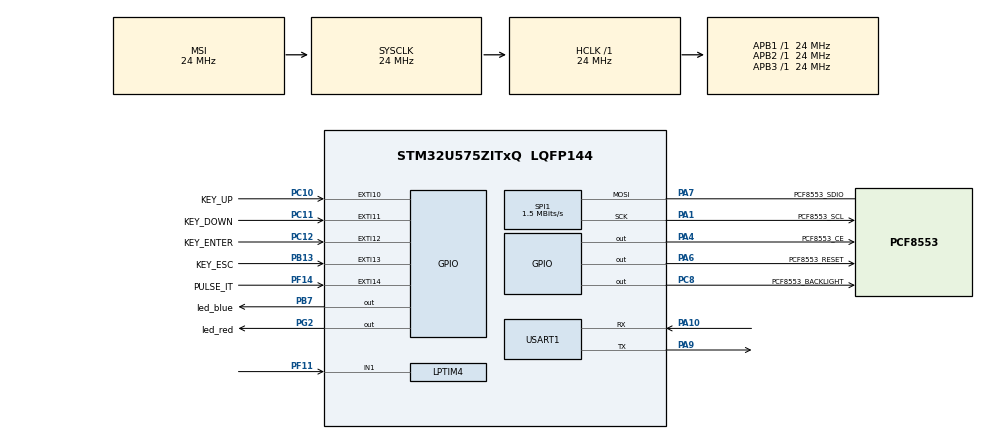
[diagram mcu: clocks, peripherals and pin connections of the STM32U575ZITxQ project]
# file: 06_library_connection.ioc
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ADC1.Channel-0\#ChannelRegularConversion=ADC_CHANNEL_TEMPSENSOR
ADC1.ClockPrescaler=ADC_CLOCK_ASYNC_DIV2
ADC1.EnableRegularConversion=ENABLE
ADC1.MonitoredBy-0\#ChannelRegularConversion=__NULL
ADC1.NbrOfConversion=1
ADC1.NbrOfConversionFlag=1
ADC1.OffsetNumber-0\#ChannelRegularConversion=ADC_OFFSET_NONE
ADC1.Rank-0\#ChannelRegularConversion=1
ADC1.Resolution=ADC_RESOLUTION_12B
ADC1.SamplingTime-0\#ChannelRegularConversion=ADC_SAMPLETIME_391CYCLES_5
ADC1.master=1
CORTEX_M33_NS.userName=CORTEX_M33
LPTIM1.ClockPrescaler=LPTIM_PRESCALER_DIV16
Mcu.Family=STM32U5
Mcu.Name=STM32U575ZITxQ
Mcu.Package=LQFP144
NVIC.EXTI10_IRQn=true\:5\:0\:true\:false\:true\:false\:true\:true\:true
NVIC.EXTI11_IRQn=true\:5\:0\:true\:false\:true\:false\:true\:true\:true
NVIC.EXTI12_IRQn=true\:5\:0\:true\:false\:true\:false\:true\:true\:true
NVIC.EXTI13_IRQn=true\:5\:0\:true\:false\:true\:false\:true\:true\:true
NVIC.EXTI14_IRQn=true\:5\:0\:true\:false\:true\:false\:true\:true\:true
NVIC.LPTIM1_IRQn=true\:0\:0\:false\:false\:true\:false\:true\:true\:true
NVIC.PriorityGroup=NVIC_PRIORITYGROUP_4
NVIC.RTC_IRQn=true\:0\:0\:false\:false\:true\:false\:true\:true\:true
NVIC.TIM6_IRQn=true\:15\:0\:false\:false\:true\:false\:false\:true\:true
NVIC.TimeBase=TIM6_IRQn
NVIC.TimeBaseIP=TIM6
PA1.GPIO_Label=PCF8553_SCL
PA1.Mode=Simplex_Bidirectional_Master
PA1.Signal=SPI1_SCK
PA10.Mode=Asynchronous
PA10.Signal=USART1_RX
PA4.GPIO_Label=PCF8553_CE
PA4.Signal=GPIO_Output
PA6.GPIO_Label=PCF8553_RESET
PA6.Signal=GPIO_Output
PA7.GPIO_Label=PCF8553_SDIO
PA7.Mode=Simplex_Bidirectional_Master
PA7.Signal=SPI1_MOSI
PA9.Mode=Asynchronous
PA9.Signal=USART1_TX
PB13.GPIO_Label=KEY_ESC
PB13.Signal=GPXTI13
PB7.GPIO_Label=led_blue
PB7.Signal=GPIO_Output
PC10.GPIO_Label=KEY_UP
PC10.Signal=GPXTI10
PC11.GPIO_Label=KEY_DOWN
PC11.Signal=GPXTI11
PC12.GPIO_Label=KEY_ENTER
PC12.Signal=GPXTI12
PC14-OSC32_IN\ (PC14).Mode=LSE-External-Oscillator
PC14-OSC32_IN\ (PC14).Signal=RCC_OSC32_IN
PC15-OSC32_OUT\ (PC15).Mode=LSE-External-Oscillator
PC15-OSC32_OUT\ (PC15).Signal=RCC_OSC32_OUT
PC8.GPIO_Label=PCF8553_BACKLIGHT
PC8.Signal=GPIO_Output
PF11.Mode=Counts_external_clock_with_synchro_01_occur1
PF11.Signal=LPTIM4_IN1
PF14.GPIO_Label=PULSE_IT
PF14.GPIO_ModeDefaultEXTI=GPIO_MODE_IT_FALLING
PF14.Signal=GPXTI14
PG2.GPIO_Label=led_red
PG2.Signal=GPIO_Output
PWR.PowerMode=PWR_SMPS_SUPPLY
ProjectManager.HeapSize=0x200
ProjectManager.StackSize=0x400
ProjectManager.TargetToolchain=STM32CubeIDE
RCC.ADCCLockSelection=RCC_ADCDACCLKSOURCE_SYSCLK
RCC.ADCFreq_Value=24000000
RCC.AHBFreq_Value=24000000
RCC.APB1Freq_Value=24000000
RCC.APB1TimFreq_Value=24000000
RCC.APB2Freq_Value=24000000
RCC.APB2TimFreq_Value=24000000
RCC.APB3Freq_Value=24000000
RCC.CortexFreq_Value=24000000
RCC.EPOD_VALUE=24000000
RCC.HCLKFreq_Value=24000000
RCC.HSE_VALUE=16000000
RCC.HSI48_VALUE=48000000
RCC.HSI_VALUE=16000000
RCC.LPTIM1CLockSelectionVirtual=RCC_LPTIM1CLKSOURCE_LSE
RCC.LPTIM3CLockSelectionVirtual=RCC_LPTIM34CLKSOURCE_LSE
RCC.LSIDIV_VALUE=32000
RCC.MSIClockRange=RCC_MSIRANGE_1
RCC.MSI_VALUE=24000000
RCC.RTCClockSelection=RCC_RTCCLKSOURCE_LSE
RCC.SYSCLKFreq_VALUE=24000000
RCC.USART1CLockSelectionVirtual=RCC_USART1CLKSOURCE_SYSCLK
RCC.USBFreq_Value=48000000
RCC.VCOOutputFreq_Value=3096000000
RTC.Date=30
RTC.Hours=9
RTC.Minutes=52
RTC.Month=RTC_MONTH_MAY
RTC.WakeUpCounter-WakeUp=4096
RTC.WeekDay=RTC_WEEKDAY_TUESDAY
RTC.Year=23
SPI1.BaudRatePrescaler=SPI_BAUDRATEPRESCALER_16
SPI1.CalculateBaudRate=1.5 MBits/s
SPI1.DataSize=SPI_DATASIZE_8BIT
SPI1.Direction=SPI_DIRECTION_1LINE
SPI1.Mode=SPI_MODE_MASTER
SPI1.NSSPMode=SPI_NSS_PULSE_DISABLE
SPI1.VirtualType=VM_MASTER
THREADX.TX_LOW_POWER=1
THREADX.TX_LOW_POWER_TICKLESS=0
THREADX.TX_LOW_POWER_TIMER_SETUP=app_threadx_lowpower_timer_setup
USART1.VirtualMode-Asynchronous=VM_ASYNC
VP_ADC1_TempSens_Input.Mode=IN-TempSens
VP_ADC1_Vref_Input.Mode=IN-Vrefint
VP_ICACHE_VS_ICACHE.Mode=DirectMappedCache
VP_LPTIM1_VS_LPTIM_counterModeInternalClock.Mode=Counts__internal_clock_event_00
VP_LPTIM3_VS_LPTIM_counterModeInternalClock.Mode=Counts__internal_clock_event_00
VP_PWR_VS_DBSignals.Mode=DisableDeadBatterySignals
VP_PWR_VS_LPOM.Mode=PowerOptimisation
VP_RTC_VS_RTC_Activate.Mode=RTC_Enabled
VP_RTC_VS_RTC_Calendar.Mode=RTC_Calendar
VP_RTC_VS_RTC_WakeUp_intern.Mode=WakeUp
VP_SYS_VS_tim6.Mode=TIM6
VP_THREADX_VS_RTOSJjThreadXJjCoreJjDefault.Mode=Core_Default
VP_THREADX_VS_RTOSJjThreadXJjLow_Power_Support.Mode=Low_Power_Support
VP_THREADX_VS_RTOSJjThreadXJjTraceX_SupportJjDefault.Mode=TraceX_Support_Default
board=custom

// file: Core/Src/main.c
/* USER CODE BEGIN Header */
/**
  ******************************************************************************
  * @file           : main.c
  * @brief          : Main program body
  ******************************************************************************
  * @attention
  *
  * Copyright (c) 2023 STMicroelectronics.
  * All rights reserved.
  *
  * This software is licensed under terms that can be found in the LICENSE file
  * in the root directory of this software component.
  * If no LICENSE file comes with this software, it is provided AS-IS.
  *
  ******************************************************************************
  */
/* USER CODE END Header */
#include "app_threadx.h"
#include "main.h"

ADC_HandleTypeDef hadc1;

LPTIM_HandleTypeDef hlptim1;
LPTIM_HandleTypeDef hlptim3;
LPTIM_HandleTypeDef hlptim4;

RTC_HandleTypeDef hrtc;

SPI_HandleTypeDef hspi1;

UART_HandleTypeDef huart1;

void SystemClock_Config(void);
static void SystemPower_Config(void);
static void MX_GPIO_Init(void);
static void MX_ADC1_Init(void);
static void MX_ICACHE_Init(void);
static void MX_LPTIM1_Init(void);
static void MX_LPTIM3_Init(void);
static void MX_LPTIM4_Init(void);
static void MX_RTC_Init(void);
static void MX_SPI1_Init(void);
static void MX_USART1_UART_Init(void);

int main(void)
{

  /* MCU Configuration--------------------------------------------------------*/

  /* Reset of all peripherals, Initializes the Flash interface and the Systick. */
  HAL_Init();

  /* Configure the system clock */
  SystemClock_Config();

  /* Configure the System Power */
  SystemPower_Config();

  /* Initialize all configured peripherals */
  MX_GPIO_Init();
  MX_ADC1_Init();
  MX_ICACHE_Init();
  MX_LPTIM1_Init();
  MX_LPTIM3_Init();
  MX_LPTIM4_Init();
  MX_RTC_Init();
  MX_SPI1_Init();
  MX_USART1_UART_Init();
  /* USER CODE BEGIN 2 */

  __HAL_RCC_RTCAPB_CLKAM_ENABLE();
  HAL_LPTIM_Counter_Start(&hlptim1);
  /* USER CODE END 2 */

  MX_ThreadX_Init();

  /* We should never get here as control is now taken by the scheduler */
  /* Infinite loop */
  while (1)
  {

  }
}

void SystemClock_Config(void)
{
  RCC_OscInitTypeDef RCC_OscInitStruct = {0};
  RCC_ClkInitTypeDef RCC_ClkInitStruct = {0};

  /** Configure the main internal regulator output voltage
  */
  if (HAL_PWREx_ControlVoltageScaling(PWR_REGULATOR_VOLTAGE_SCALE4) != HAL_OK)
  {
    Error_Handler();
  }

  /** Configure LSE Drive Capability
  */
  HAL_PWR_EnableBkUpAccess();
  __HAL_RCC_LSEDRIVE_CONFIG(RCC_LSEDRIVE_LOW);

  /** Initializes the CPU, AHB and APB buses clocks
  */
  RCC_OscInitStruct.OscillatorType = RCC_OSCILLATORTYPE_LSE|RCC_OSCILLATORTYPE_MSI;
  RCC_OscInitStruct.LSEState = RCC_LSE_ON;
  RCC_OscInitStruct.MSIState = RCC_MSI_ON;
  RCC_OscInitStruct.MSICalibrationValue = RCC_MSICALIBRATION_DEFAULT;
  RCC_OscInitStruct.MSIClockRange = RCC_MSIRANGE_1;
  RCC_OscInitStruct.PLL.PLLState = RCC_PLL_NONE;
  if (HAL_RCC_OscConfig(&RCC_OscInitStruct) != HAL_OK)
  {
    Error_Handler();
  }

  /** Initializes the CPU, AHB and APB buses clocks
  */
  RCC_ClkInitStruct.ClockType = RCC_CLOCKTYPE_HCLK|RCC_CLOCKTYPE_SYSCLK
                              |RCC_CLOCKTYPE_PCLK1|RCC_CLOCKTYPE_PCLK2
                              |RCC_CLOCKTYPE_PCLK3;
  RCC_ClkInitStruct.SYSCLKSource = RCC_SYSCLKSOURCE_MSI;
  RCC_ClkInitStruct.AHBCLKDivider = RCC_SYSCLK_DIV1;
  RCC_ClkInitStruct.APB1CLKDivider = RCC_HCLK_DIV1;
  RCC_ClkInitStruct.APB2CLKDivider = RCC_HCLK_DIV1;
  RCC_ClkInitStruct.APB3CLKDivider = RCC_HCLK_DIV1;

  if (HAL_RCC_ClockConfig(&RCC_ClkInitStruct, FLASH_LATENCY_1) != HAL_OK)
  {
    Error_Handler();
  }
}

/**
  * @brief Power Configuration
  * @retval None
  */
static void SystemPower_Config(void)
{
  HAL_PWREx_EnableVddIO2();

  /*
   * Disable the internal Pull-Up in Dead Battery pins of UCPD peripheral
   */
  HAL_PWREx_DisableUCPDDeadBattery();

  /*
   * Switch to SMPS regulator instead of LDO
   */
  if (HAL_PWREx_ConfigSupply(PWR_SMPS_SUPPLY) != HAL_OK)
  {
    Error_Handler();
  }
}

static void MX_ADC1_Init(void)
{

  ADC_ChannelConfTypeDef sConfig = {0};

  /** Common config
  */
  hadc1.Instance = ADC1;
  hadc1.Init.ClockPrescaler = ADC_CLOCK_ASYNC_DIV2;
  hadc1.Init.Resolution = ADC_RESOLUTION_12B;
  hadc1.Init.GainCompensation = 0;
  hadc1.Init.ScanConvMode = ADC_SCAN_DISABLE;
  hadc1.Init.EOCSelection = ADC_EOC_SINGLE_CONV;
  hadc1.Init.LowPowerAutoWait = DISABLE;
  hadc1.Init.ContinuousConvMode = DISABLE;
  hadc1.Init.NbrOfConversion = 1;
  hadc1.Init.DiscontinuousConvMode = DISABLE;
  hadc1.Init.ExternalTrigConv = ADC_SOFTWARE_START;
  hadc1.Init.ExternalTrigConvEdge = ADC_EXTERNALTRIGCONVEDGE_NONE;
  hadc1.Init.DMAContinuousRequests = DISABLE;
  hadc1.Init.TriggerFrequencyMode = ADC_TRIGGER_FREQ_HIGH;
  hadc1.Init.Overrun = ADC_OVR_DATA_PRESERVED;
  hadc1.Init.LeftBitShift = ADC_LEFTBITSHIFT_NONE;
  hadc1.Init.ConversionDataManagement = ADC_CONVERSIONDATA_DR;
  hadc1.Init.OversamplingMode = DISABLE;
  if (HAL_ADC_Init(&hadc1) != HAL_OK)
  {
    Error_Handler();
  }

  /** Configure Regular Channel
  */
  sConfig.Channel = ADC_CHANNEL_TEMPSENSOR;
  sConfig.Rank = ADC_REGULAR_RANK_1;
  sConfig.SamplingTime = ADC_SAMPLETIME_391CYCLES_5;
  sConfig.SingleDiff = ADC_SINGLE_ENDED;
  sConfig.OffsetNumber = ADC_OFFSET_NONE;
  sConfig.Offset = 0;
  if (HAL_ADC_ConfigChannel(&hadc1, &sConfig) != HAL_OK)
  {
    Error_Handler();
  }

}

static void MX_ICACHE_Init(void)
{

  /** Enable instruction cache in 1-way (direct mapped cache)
  */
  if (HAL_ICACHE_ConfigAssociativityMode(ICACHE_1WAY) != HAL_OK)
  {
    Error_Handler();
  }
  if (HAL_ICACHE_Enable() != HAL_OK)
  {
    Error_Handler();
  }

}

static void MX_LPTIM1_Init(void)
{

  hlptim1.Instance = LPTIM1;
  hlptim1.Init.Clock.Source = LPTIM_CLOCKSOURCE_APBCLOCK_LPOSC;
  hlptim1.Init.Clock.Prescaler = LPTIM_PRESCALER_DIV16;
  hlptim1.Init.Trigger.Source = LPTIM_TRIGSOURCE_SOFTWARE;
  hlptim1.Init.Period = 65535;
  hlptim1.Init.UpdateMode = LPTIM_UPDATE_IMMEDIATE;
  hlptim1.Init.CounterSource = LPTIM_COUNTERSOURCE_INTERNAL;
  hlptim1.Init.Input1Source = LPTIM_INPUT1SOURCE_GPIO;
  hlptim1.Init.Input2Source = LPTIM_INPUT2SOURCE_GPIO;
  hlptim1.Init.RepetitionCounter = 0;
  if (HAL_LPTIM_Init(&hlptim1) != HAL_OK)
  {
    Error_Handler();
  }
  /* USER CODE BEGIN LPTIM1_Init 2 */

  /*
   * To run in stop mode the LPBAM low-power backgroung autonomous mode must be
   * configured
   *
   */
  __HAL_RCC_LPTIM1_CLKAM_ENABLE();
  __HAL_RCC_LPDMA1_CLKAM_ENABLE();
  __HAL_RCC_SRAM4_CLKAM_ENABLE();

  /* USER CODE END LPTIM1_Init 2 */

}

static void MX_LPTIM3_Init(void)
{

  hlptim3.Instance = LPTIM3;
  hlptim3.Init.Clock.Source = LPTIM_CLOCKSOURCE_APBCLOCK_LPOSC;
  hlptim3.Init.Clock.Prescaler = LPTIM_PRESCALER_DIV1;
  hlptim3.Init.Trigger.Source = LPTIM_TRIGSOURCE_SOFTWARE;
  hlptim3.Init.Period = 65535;
  hlptim3.Init.UpdateMode = LPTIM_UPDATE_IMMEDIATE;
  hlptim3.Init.CounterSource = LPTIM_COUNTERSOURCE_INTERNAL;
  hlptim3.Init.Input1Source = LPTIM_INPUT1SOURCE_GPIO;
  hlptim3.Init.Input2Source = LPTIM_INPUT2SOURCE_GPIO;
  hlptim3.Init.RepetitionCounter = 0;
  if (HAL_LPTIM_Init(&hlptim3) != HAL_OK)
  {
    Error_Handler();
  }
  /* USER CODE BEGIN LPTIM3_Init 2 */
  __HAL_RCC_LPTIM3_CLKAM_ENABLE();
  /* USER CODE END LPTIM3_Init 2 */

}

static void MX_LPTIM4_Init(void)
{

  hlptim4.Instance = LPTIM4;
  hlptim4.Init.Clock.Source = LPTIM_CLOCKSOURCE_APBCLOCK_LPOSC;
  hlptim4.Init.Clock.Prescaler = LPTIM_PRESCALER_DIV1;
  hlptim4.Init.UltraLowPowerClock.Polarity = LPTIM_CLOCKPOLARITY_RISING;
  hlptim4.Init.UltraLowPowerClock.SampleTime = LPTIM_CLOCKSAMPLETIME_DIRECTTRANSITION;
  hlptim4.Init.Trigger.Source = LPTIM_TRIGSOURCE_SOFTWARE;
  hlptim4.Init.Period = 65535;
  hlptim4.Init.UpdateMode = LPTIM_UPDATE_IMMEDIATE;
  hlptim4.Init.CounterSource = LPTIM_COUNTERSOURCE_EXTERNAL;
  hlptim4.Init.Input1Source = LPTIM_INPUT1SOURCE_GPIO;
  hlptim4.Init.Input2Source = LPTIM_INPUT2SOURCE_GPIO;
  hlptim4.Init.RepetitionCounter = 0;
  if (HAL_LPTIM_Init(&hlptim4) != HAL_OK)
  {
    Error_Handler();
  }
  /* USER CODE BEGIN LPTIM4_Init 2 */
  __HAL_RCC_LPTIM4_CLKAM_ENABLE();
  /* USER CODE END LPTIM4_Init 2 */

}

static void MX_RTC_Init(void)
{

  RTC_PrivilegeStateTypeDef privilegeState = {0};
  RTC_TimeTypeDef sTime = {0};
  RTC_DateTypeDef sDate = {0};

  /** Initialize RTC Only
  */
  hrtc.Instance = RTC;
  hrtc.Init.HourFormat = RTC_HOURFORMAT_24;
  hrtc.Init.AsynchPrediv = 127;
  hrtc.Init.SynchPrediv = 255;
  hrtc.Init.OutPut = RTC_OUTPUT_DISABLE;
  hrtc.Init.OutPutRemap = RTC_OUTPUT_REMAP_NONE;
  hrtc.Init.OutPutPolarity = RTC_OUTPUT_POLARITY_HIGH;
  hrtc.Init.OutPutType = RTC_OUTPUT_TYPE_OPENDRAIN;
  hrtc.Init.OutPutPullUp = RTC_OUTPUT_PULLUP_NONE;
  hrtc.Init.BinMode = RTC_BINARY_NONE;
  if (HAL_RTC_Init(&hrtc) != HAL_OK)
  {
    Error_Handler();
  }
  privilegeState.rtcPrivilegeFull = RTC_PRIVILEGE_FULL_NO;
  privilegeState.backupRegisterPrivZone = RTC_PRIVILEGE_BKUP_ZONE_NONE;
  privilegeState.backupRegisterStartZone2 = RTC_BKP_DR0;
  privilegeState.backupRegisterStartZone3 = RTC_BKP_DR0;
  if (HAL_RTCEx_PrivilegeModeSet(&hrtc, &privilegeState) != HAL_OK)
  {
    Error_Handler();
  }

  /** Initialize RTC and set the Time and Date
  */
  sTime.Hours = 0x9;
  sTime.Minutes = 0x52;
  sTime.Seconds = 0x0;
  sTime.DayLightSaving = RTC_DAYLIGHTSAVING_NONE;
  sTime.StoreOperation = RTC_STOREOPERATION_RESET;
  if (HAL_RTC_SetTime(&hrtc, &sTime, RTC_FORMAT_BCD) != HAL_OK)
  {
    Error_Handler();
  }
  sDate.WeekDay = RTC_WEEKDAY_TUESDAY;
  sDate.Month = RTC_MONTH_MAY;
  sDate.Date = 0x30;
  sDate.Year = 0x23;

  if (HAL_RTC_SetDate(&hrtc, &sDate, RTC_FORMAT_BCD) != HAL_OK)
  {
    Error_Handler();
  }

  /** Enable the WakeUp
  */
  if (HAL_RTCEx_SetWakeUpTimer_IT(&hrtc, 4096, RTC_WAKEUPCLOCK_RTCCLK_DIV16, 0) != HAL_OK)
  {
    Error_Handler();
  }

}

static void MX_SPI1_Init(void)
{

  SPI_AutonomousModeConfTypeDef HAL_SPI_AutonomousMode_Cfg_Struct = {0};

  /* SPI1 parameter configuration*/
  hspi1.Instance = SPI1;
  hspi1.Init.Mode = SPI_MODE_MASTER;
  hspi1.Init.Direction = SPI_DIRECTION_1LINE;
  hspi1.Init.DataSize = SPI_DATASIZE_8BIT;
  hspi1.Init.CLKPolarity = SPI_POLARITY_LOW;
  hspi1.Init.CLKPhase = SPI_PHASE_1EDGE;
  hspi1.Init.NSS = SPI_NSS_SOFT;
  hspi1.Init.BaudRatePrescaler = SPI_BAUDRATEPRESCALER_16;
  hspi1.Init.FirstBit = SPI_FIRSTBIT_MSB;
  hspi1.Init.TIMode = SPI_TIMODE_DISABLE;
  hspi1.Init.CRCCalculation = SPI_CRCCALCULATION_DISABLE;
  hspi1.Init.CRCPolynomial = 0x7;
  hspi1.Init.NSSPMode = SPI_NSS_PULSE_DISABLE;
  hspi1.Init.NSSPolarity = SPI_NSS_POLARITY_LOW;
  hspi1.Init.FifoThreshold = SPI_FIFO_THRESHOLD_01DATA;
  hspi1.Init.MasterSSIdleness = SPI_MASTER_SS_IDLENESS_00CYCLE;
  hspi1.Init.MasterInterDataIdleness = SPI_MASTER_INTERDATA_IDLENESS_00CYCLE;
  hspi1.Init.MasterReceiverAutoSusp = SPI_MASTER_RX_AUTOSUSP_DISABLE;
  hspi1.Init.MasterKeepIOState = SPI_MASTER_KEEP_IO_STATE_DISABLE;
  hspi1.Init.IOSwap = SPI_IO_SWAP_DISABLE;
  hspi1.Init.ReadyMasterManagement = SPI_RDY_MASTER_MANAGEMENT_INTERNALLY;
  hspi1.Init.ReadyPolarity = SPI_RDY_POLARITY_HIGH;
  if (HAL_SPI_Init(&hspi1) != HAL_OK)
  {
    Error_Handler();
  }
  HAL_SPI_AutonomousMode_Cfg_Struct.TriggerState = SPI_AUTO_MODE_DISABLE;
  HAL_SPI_AutonomousMode_Cfg_Struct.TriggerSelection = SPI_GRP1_GPDMA_CH0_TCF_TRG;
  HAL_SPI_AutonomousMode_Cfg_Struct.TriggerPolarity = SPI_TRIG_POLARITY_RISING;
  if (HAL_SPIEx_SetConfigAutonomousMode(&hspi1, &HAL_SPI_AutonomousMode_Cfg_Struct) != HAL_OK)
  {
    Error_Handler();
  }

}

static void MX_USART1_UART_Init(void)
{

  huart1.Instance = USART1;
  huart1.Init.BaudRate = 115200;
  huart1.Init.WordLength = UART_WORDLENGTH_8B;
  huart1.Init.StopBits = UART_STOPBITS_1;
  huart1.Init.Parity = UART_PARITY_NONE;
  huart1.Init.Mode = UART_MODE_TX_RX;
  huart1.Init.HwFlowCtl = UART_HWCONTROL_NONE;
  huart1.Init.OverSampling = UART_OVERSAMPLING_16;
  huart1.Init.OneBitSampling = UART_ONE_BIT_SAMPLE_DISABLE;
  huart1.Init.ClockPrescaler = UART_PRESCALER_DIV1;
  huart1.AdvancedInit.AdvFeatureInit = UART_ADVFEATURE_NO_INIT;
  if (HAL_UART_Init(&huart1) != HAL_OK)
  {
    Error_Handler();
  }
  if (HAL_UARTEx_SetTxFifoThreshold(&huart1, UART_TXFIFO_THRESHOLD_1_8) != HAL_OK)
  {
    Error_Handler();
  }
  if (HAL_UARTEx_SetRxFifoThreshold(&huart1, UART_RXFIFO_THRESHOLD_1_8) != HAL_OK)
  {
    Error_Handler();
  }
  if (HAL_UARTEx_DisableFifoMode(&huart1) != HAL_OK)
  {
    Error_Handler();
  }

}

static void MX_GPIO_Init(void)
{
  GPIO_InitTypeDef GPIO_InitStruct = {0};

  /* GPIO Ports Clock Enable */
  __HAL_RCC_GPIOC_CLK_ENABLE();
  __HAL_RCC_GPIOA_CLK_ENABLE();
  __HAL_RCC_GPIOF_CLK_ENABLE();
  __HAL_RCC_GPIOB_CLK_ENABLE();
  __HAL_RCC_GPIOG_CLK_ENABLE();

  /*Configure GPIO pin Output Level */
  HAL_GPIO_WritePin(GPIOA, PCF8553_CE_Pin|PCF8553_RESET_Pin, GPIO_PIN_RESET);

  /*Configure GPIO pin Output Level */
  HAL_GPIO_WritePin(led_red_GPIO_Port, led_red_Pin, GPIO_PIN_RESET);

  /*Configure GPIO pin Output Level */
  HAL_GPIO_WritePin(PCF8553_BACKLIGHT_GPIO_Port, PCF8553_BACKLIGHT_Pin, GPIO_PIN_RESET);

  /*Configure GPIO pin Output Level */
  HAL_GPIO_WritePin(led_blue_GPIO_Port, led_blue_Pin, GPIO_PIN_RESET);

  /*Configure GPIO pins : PCF8553_CE_Pin PCF8553_RESET_Pin */
  GPIO_InitStruct.Pin = PCF8553_CE_Pin|PCF8553_RESET_Pin;
  GPIO_InitStruct.Mode = GPIO_MODE_OUTPUT_PP;
  GPIO_InitStruct.Pull = GPIO_NOPULL;
  GPIO_InitStruct.Speed = GPIO_SPEED_FREQ_LOW;
  HAL_GPIO_Init(GPIOA, &GPIO_InitStruct);

  /*Configure GPIO pin : PULSE_IT_Pin */
  GPIO_InitStruct.Pin = PULSE_IT_Pin;
  GPIO_InitStruct.Mode = GPIO_MODE_IT_FALLING;
  GPIO_InitStruct.Pull = GPIO_NOPULL;
  HAL_GPIO_Init(PULSE_IT_GPIO_Port, &GPIO_InitStruct);

  /*Configure GPIO pin : KEY_ESC_Pin */
  GPIO_InitStruct.Pin = KEY_ESC_Pin;
  GPIO_InitStruct.Mode = GPIO_MODE_IT_RISING;
  GPIO_InitStruct.Pull = GPIO_NOPULL;
  HAL_GPIO_Init(KEY_ESC_GPIO_Port, &GPIO_InitStruct);

  /*Configure GPIO pin : led_red_Pin */
  GPIO_InitStruct.Pin = led_red_Pin;
  GPIO_InitStruct.Mode = GPIO_MODE_OUTPUT_PP;
  GPIO_InitStruct.Pull = GPIO_NOPULL;
  GPIO_InitStruct.Speed = GPIO_SPEED_FREQ_LOW;
  HAL_GPIO_Init(led_red_GPIO_Port, &GPIO_InitStruct);

  /*Configure GPIO pin : PCF8553_BACKLIGHT_Pin */
  GPIO_InitStruct.Pin = PCF8553_BACKLIGHT_Pin;
  GPIO_InitStruct.Mode = GPIO_MODE_OUTPUT_PP;
  GPIO_InitStruct.Pull = GPIO_NOPULL;
  GPIO_InitStruct.Speed = GPIO_SPEED_FREQ_LOW;
  HAL_GPIO_Init(PCF8553_BACKLIGHT_GPIO_Port, &GPIO_InitStruct);

  /*Configure GPIO pins : KEY_UP_Pin KEY_DOWN_Pin KEY_ENTER_Pin */
  GPIO_InitStruct.Pin = KEY_UP_Pin|KEY_DOWN_Pin|KEY_ENTER_Pin;
  GPIO_InitStruct.Mode = GPIO_MODE_IT_RISING;
  GPIO_InitStruct.Pull = GPIO_NOPULL;
  HAL_GPIO_Init(GPIOC, &GPIO_InitStruct);

  /*Configure GPIO pin : led_blue_Pin */
  GPIO_InitStruct.Pin = led_blue_Pin;
  GPIO_InitStruct.Mode = GPIO_MODE_OUTPUT_PP;
  GPIO_InitStruct.Pull = GPIO_NOPULL;
  GPIO_InitStruct.Speed = GPIO_SPEED_FREQ_LOW;
  HAL_GPIO_Init(led_blue_GPIO_Port, &GPIO_InitStruct);

  /* EXTI interrupt init*/
  HAL_NVIC_SetPriority(EXTI10_IRQn, 5, 0);
  HAL_NVIC_EnableIRQ(EXTI10_IRQn);

  HAL_NVIC_SetPriority(EXTI11_IRQn, 5, 0);
  HAL_NVIC_EnableIRQ(EXTI11_IRQn);

  HAL_NVIC_SetPriority(EXTI12_IRQn, 5, 0);
  HAL_NVIC_EnableIRQ(EXTI12_IRQn);

  HAL_NVIC_SetPriority(EXTI13_IRQn, 5, 0);
  HAL_NVIC_EnableIRQ(EXTI13_IRQn);

  HAL_NVIC_SetPriority(EXTI14_IRQn, 5, 0);
  HAL_NVIC_EnableIRQ(EXTI14_IRQn);

}

/* USER CODE BEGIN 4 */

__weak void HAL_RTCEx_WakeUpTimerEventCallback(RTC_HandleTypeDef *hrtc)
{
    /* Prevent unused argument(s) compilation warning */
    UNUSED(hrtc);
    HAL_RTCEx_DeactivateWakeUpTimer(hrtc);
}

/* USER CODE END 4 */

void HAL_TIM_PeriodElapsedCallback(TIM_HandleTypeDef *htim)
{
  if (htim->Instance == TIM6) {
    HAL_IncTick();
  }
}

void Error_Handler(void)
{
  /* USER CODE BEGIN Error_Handler_Debug */
  /* User can add his own implementation to report the HAL error return state */
  __disable_irq();
  HAL_GPIO_TogglePin(led_red_GPIO_Port, led_red_Pin);
  while (1)
  {

  }
  /* USER CODE END Error_Handler_Debug */
}
